AUTOSAR XML
package /Cluster
  can cluster CAN: speed=50000
    physical channels CAN
      physical-channel:
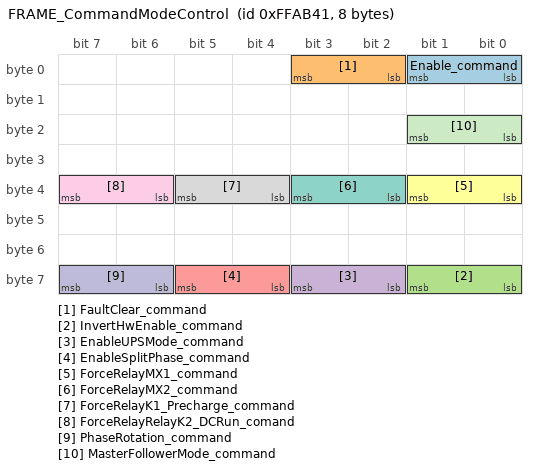
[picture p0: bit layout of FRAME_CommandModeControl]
        frame FRAME_CommandModeControl: id 0xFFAB41, frame-length=8, can-addressing-mode=EXTENDED
          pdu PDU_CommandModeControl: length=64
            signal Enable_command: start 1, 2 bit, big-endian, data-type=DataType/Enable_command
            signal FaultClear_command: start 3, 2 bit, big-endian, data-type=DataType/FaultClear_command
            signal InvertHwEnable_command: start 57, 2 bit, big-endian, data-type=DataType/InvertHwEnable_command
            signal EnableUPSMode_command: start 59, 2 bit, big-endian, data-type=DataType/EnableUPSMode_command
            signal EnableSplitPhase_command: start 61, 2 bit, big-endian, data-type=DataType/EnableSplitPhase_command
            signal ForceRelayMX1_command: start 33, 2 bit, big-endian, data-type=DataType/ForceRelayMX1_command
            signal ForceRelayMX2_command: start 35, 2 bit, big-endian, data-type=DataType/ForceRelayMX2_command
            signal ForceRelayK1_Precharge_command: start 37, 2 bit, big-endian, data-type=DataType/ForceRelayK1_Precharge_command
            signal ForceRelayRelayK2_DCRun_comand: start 39, 2 bit, big-endian, data-type=DataType/ForceRelayRelayK2_DCRun_comand
            signal PhaseRotation_command: start 63, 2 bit, big-endian, data-type=DataType/PhaseRotation_command
            signal MasterFollowerMode_command: start 17, 2 bit, big-endian, data-type=DataType/MasterFollowerMode_command
        frame FRAME_CommandPower: id 0xCFFAC41, frame-length=8, can-addressing-mode=EXTENDED
          pdu PDU_CommandPower: length=64
            signal RealPower command: start 7, 32 bit, big-endian, data-type=RealPower command
            signal ReactivePower_command: start 39, 32 bit, big-endian, data-type=DataType/ReactivePower_command
        frame FRAME_CommandVF: id 0xCFFAE41, frame-length=8, can-addressing-mode=EXTENDED
          pdu PDU_CommandVF: length=64
            signal Voltage_command: start 7, 16 bit, big-endian, data-type=DataType/Voltage_command
            signal Frequency_command: start 23, 16 bit, big-endian, data-type=DataType/Frequency_command
        frame FRAME_MasterMeasuredPower: id 0xCFFCAF6, frame-length=8, can-addressing-mode=EXTENDED
          pdu PDU_MasterMeasuredPower: length=64
            signal RealPower_measured: start 7, 32 bit, big-endian, data-type=DataType/RealPower_measured
            signal ReactivePower_measured: start 39, 32 bit, big-endian, data-type=DataType/ReactivePower_measured
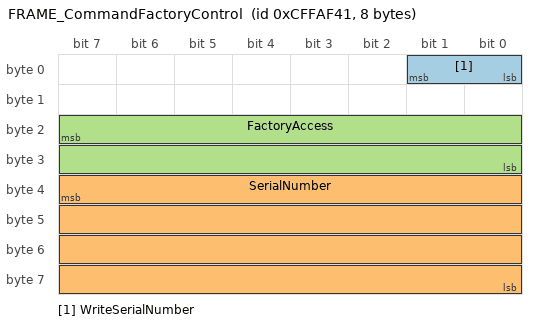
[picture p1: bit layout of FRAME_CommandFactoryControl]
        frame FRAME_CommandFactoryControl: id 0xCFFAF41, frame-length=8, can-addressing-mode=EXTENDED
          pdu PDU_CommandFactoryControl: length=64
            signal WriteSerialNumber: start 1, 2 bit, big-endian, data-type=WriteSerialNumber
            signal SerialNumber: start 39, 32 bit, big-endian, data-type=DataType/SerialNumber
            signal FactoryAccess: start 23, 16 bit, big-endian, data-type=FactoryAccess
        frame FRAME_CommandSetNVParam: id 0xCFFAA41, frame-length=8, can-addressing-mode=EXTENDED
          pdu PDU_CommandSetNVParam: length=64
            signal CommandSetNVParam_MUX: start 7, 16 bit, big-endian, data-type=CommandSetNVParam_MUX
            signal Dummy: start 23, 16 bit, big-endian, data-type=DataType/Dummy
            signal VUnder50pct: start 23, 16 bit, big-endian, data-type=DataType/VUnder50pct
            signal V50to88pct: start 39, 16 bit, big-endian, data-type=DataType/V50to88pct
            signal V110to120pct: start 55, 16 bit, big-endian, data-type=DataType/V110to120pct
            signal VOver120: start 23, 16 bit, big-endian, data-type=DataType/VOver120
            signal FreqHi: start 23, 16 bit, big-endian, data-type=DataType/FreqHi
            signal FreqLo: start 39, 16 bit, big-endian, data-type=DataType/FreqLo
            signal FreqVeryLo: start 55, 16 bit, big-endian, data-type=DataType/FreqVeryLo
            signal FreqVeryLo: start 23, 16 bit, big-endian, data-type=DataType/FreqVeryLo
            signal FreqLo: start 39, 16 bit, big-endian, data-type=DataType/FreqLo
            signal FreqHi: start 55, 16 bit, big-endian, data-type=DataType/FreqHi
            signal NodeID: start 23, 8 bit, big-endian, data-type=NodeID
            signal SA_Mask: start 31, 8 bit, big-endian, data-type=SA_Mask
            signal Baudrate: start 39, 4 bit, big-endian, data-type=Baudrate
            signal ThermalOverload: start 17, 2 bit, big-endian, data-type=DataType/ThermalOverload
            signal MX1Open: start 23, 16 bit, big-endian, data-type=MX1Open
            signal MX1Close: start 39, 16 bit, big-endian, data-type=MX1Close
            signal MX2Open: start 55, 16 bit, big-endian, data-type=MX2Open
            signal MX2Close: start 23, 16 bit, big-endian, data-type=MX2Close
            signal K1Open: start 39, 16 bit, big-endian, data-type=K1Open
            signal K1Close: start 55, 16 bit, big-endian, data-type=K1Close
            signal K2Open: start 23, 16 bit, big-endian, data-type=K2Open
            signal K2Close: start 39, 16 bit, big-endian, data-type=K2Close
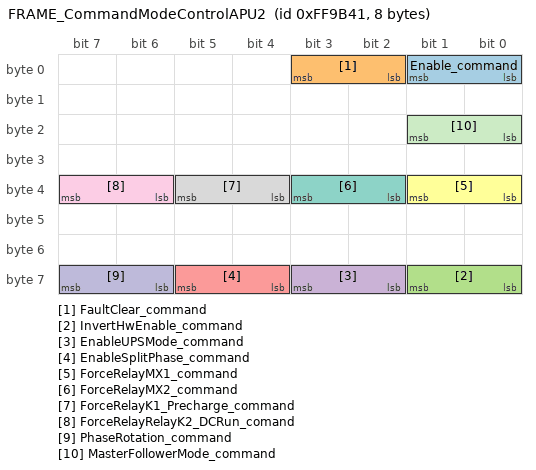
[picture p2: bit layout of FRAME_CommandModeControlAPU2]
        frame FRAME_CommandModeControlAPU2: id 0xFF9B41, frame-length=8, can-addressing-mode=EXTENDED
          pdu PDU_CommandModeControlAPU2: length=64
            signal Enable_command: start 1, 2 bit, big-endian, data-type=DataType/Enable_command
            signal FaultClear_command: start 3, 2 bit, big-endian, data-type=DataType/FaultClear_command
            signal InvertHwEnable_command: start 57, 2 bit, big-endian, data-type=DataType/InvertHwEnable_command
            signal EnableUPSMode_command: start 59, 2 bit, big-endian, data-type=DataType/EnableUPSMode_command
            signal EnableSplitPhase_command: start 61, 2 bit, big-endian, data-type=DataType/EnableSplitPhase_command
            signal ForceRelayMX1_command: start 33, 2 bit, big-endian, data-type=DataType/ForceRelayMX1_command
            signal ForceRelayMX2_command: start 35, 2 bit, big-endian, data-type=DataType/ForceRelayMX2_command
            signal ForceRelayK1_Precharge_command: start 37, 2 bit, big-endian, data-type=DataType/ForceRelayK1_Precharge_command
            signal ForceRelayRelayK2_DCRun_comand: start 39, 2 bit, big-endian, data-type=DataType/ForceRelayRelayK2_DCRun_comand
            signal PhaseRotation_command: start 63, 2 bit, big-endian, data-type=DataType/PhaseRotation_command
            signal MasterFollowerMode_command: start 17, 2 bit, big-endian, data-type=DataType/MasterFollowerMode_command
        frame FRAME_CommandPowerAPU2: id 0xCFF9C41, frame-length=8, can-addressing-mode=EXTENDED
          pdu PDU_CommandPowerAPU2: length=64
            signal RealPower_command: start 7, 32 bit, big-endian, data-type=RealPower_command
            signal ReactivePower_command: start 39, 32 bit, big-endian, data-type=DataType/ReactivePower_command
        frame FRAME_CommandVFAPU2: id 0xCFF9E41, frame-length=8, can-addressing-mode=EXTENDED
          pdu PDU_CommandVFAPU2: length=64
            signal Voltage_command: start 7, 16 bit, big-endian, data-type=DataType/Voltage_command
            signal Frequency_command: start 23, 16 bit, big-endian, data-type=DataType/Frequency_command
        frame FRAME_MasterMeasuredPowerAPU2: id 0xCFFCAF7, frame-length=8, can-addressing-mode=EXTENDED
          pdu PDU_MasterMeasuredPowerAPU2: length=64
            signal RealPower_measured: start 7, 32 bit, big-endian, data-type=DataType/RealPower_measured
            signal ReactivePower_measured: start 39, 32 bit, big-endian, data-type=DataType/ReactivePower_measured
        frame FRAME_justString: id 0x1CFFACC0, frame-length=8, can-addressing-mode=EXTENDED
          pdu PDU_justString: length=64
        frame FRAME_stringAndOther: id 0x1CFFABC0, frame-length=8, can-addressing-mode=EXTENDED
          pdu PDU_stringAndOther: length=64
            signal RealPower_measured: start 7, 32 bit, big-endian, data-type=DataType/RealPower_measured
        frame FRAME_StatusMeasuredPower: id 0xCFFCAF7, frame-length=8, can-addressing-mode=EXTENDED
          pdu PDU_StatusMeasuredPower: length=64
            signal RealPower_measured: start 7, 32 bit, big-endian, data-type=DataType/RealPower_measured
            signal ReactivePower_measured: start 39, 32 bit, big-endian, data-type=DataType/ReactivePower_measured
        frame FRAME_StatusCommandedPower: id 0x18FFC4F7, frame-length=8, can-addressing-mode=EXTENDED
          pdu PDU_StatusCommandedPower: length=64
            signal RealPower_echo: start 7, 32 bit, big-endian, data-type=RealPower_echo
            signal ReactivePower_echo: start 39, 32 bit, big-endian, data-type=ReactivePower_echo
        frame FRAME_StatusBits: id 0xCFFC3F7, frame-length=8, can-addressing-mode=EXTENDED
          pdu PDU_StatusBits: length=64
            signal State_status: start 3, 4 bit, big-endian, data-type=State_status
            signal MX2Permissive_status: start 19, 2 bit, big-endian, data-type=MX2Permissive_status
            signal PowerAvailAC_status: start 11, 2 bit, big-endian, data-type=PowerAvailAC_status
            signal PowerAvailDC_status: start 13, 2 bit, big-endian, data-type=PowerAvailDC_status
            signal PowerCircuitEnabled_status: start 15, 2 bit, big-endian, data-type=PowerCircuitEnabled_status
            signal HardwareEnable_status: start 9, 2 bit, big-endian, data-type=HardwareEnable_status
            signal Enable_echo: start 5, 2 bit, big-endian, data-type=Enable_echo
            signal FaultClr_echo: start 7, 2 bit, big-endian, data-type=FaultClr_echo
            signal MessageValidModeControl_status: start 25, 2 bit, big-endian, data-type=MessageValidModeControl_status
            signal MX1Permissive_status: start 17, 2 bit, big-endian, data-type=MX1Permissive_status
            signal K2DCRunPermissive_status: start 23, 2 bit, big-endian, data-type=K2DCRunPermissive_status
            signal K1PrechargePermissive_status: start 21, 2 bit, big-endian, data-type=K1PrechargePermissive_status
            signal MessageValidPowerCMD_status: start 27, 2 bit, big-endian, data-type=MessageValidPowerCMD_status
            signal MessageValidVF_status: start 29, 2 bit, big-endian, data-type=MessageValidVF_status
            signal CANbus_status: start 31, 2 bit, big-endian, data-type=CANbus_status
            signal EnableUPSMode_echo: start 33, 2 bit, big-endian, data-type=EnableUPSMode_echo
            signal EnableSplitPhase_echo: start 35, 2 bit, big-endian, data-type=EnableSplitPhase_echo
            signal PhaseRotation_status: start 37, 2 bit, big-endian, data-type=PhaseRotation_status
            signal LineVoltageDetected_status: start 39, 2 bit, big-endian, data-type=LineVoltageDetected_status
            signal PhaseRotation_echo: start 41, 2 bit, big-endian, data-type=PhaseRotation_echo
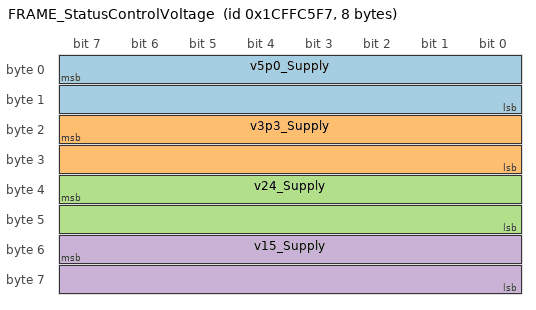
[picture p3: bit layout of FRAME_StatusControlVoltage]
        frame FRAME_StatusControlVoltage: id 0x1CFFC5F7, frame-length=8, can-addressing-mode=EXTENDED
          pdu PDU_StatusControlVoltage: length=64
            signal v5p0_Supply: start 7, 16 bit, big-endian, data-type=v5p0_Supply
            signal v3p3_Supply: start 23, 16 bit, big-endian, data-type=v3p3_Supply
            signal v24_Supply: start 39, 16 bit, big-endian, data-type=v24_Supply
            signal v15_Supply: start 55, 16 bit, big-endian, data-type=v15_Supply
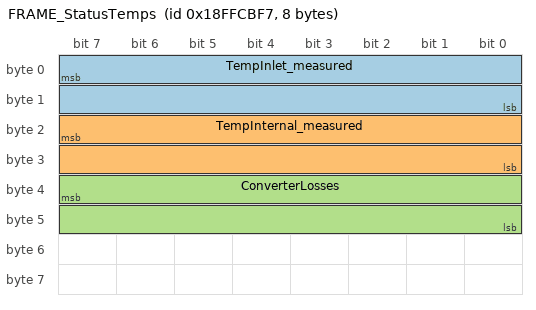
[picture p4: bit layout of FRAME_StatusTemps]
        frame FRAME_StatusTemps: id 0x18FFCBF7, frame-length=8, can-addressing-mode=EXTENDED
          pdu PDU_StatusTemps: length=64
            signal TempInlet_measured: start 7, 16 bit, big-endian, data-type=TempInlet_measured
            signal TempInternal_measured: start 23, 16 bit, big-endian, data-type=TempInternal_measured
            signal ConverterLosses: start 39, 16 bit, big-endian, data-type=ConverterLosses
        frame FRAME_StatusFaults: id 0xCFFC8F7, frame-length=8, can-addressing-mode=EXTENDED
          pdu PDU_StatusFaults: length=64
            signal BridgeAVoltageOk_status: start 59, 1 bit, big-endian, data-type=BridgeAVoltageOk_status
            signal OvercurrentAC_status: start 3, 2 bit, big-endian, data-type=OvercurrentAC_status
            signal BridgeBVoltageOk_status: start 43, 1 bit, big-endian, data-type=BridgeBVoltageOk_status
            signal OvervoltageDC_status: start 9, 2 bit, big-endian, data-type=OvervoltageDC_status
            signal OvertempPowerDevice_status: start 15, 2 bit, big-endian, data-type=OvertempPowerDevice_status
            signal OvertempInternal_status: start 13, 2 bit, big-endian, data-type=OvertempInternal_status
            signal LossValidControlMessage_status: start 23, 4 bit, big-endian, data-type=LossValidControlMessage_status
            signal UndervoltageDC_status: start 11, 2 bit, big-endian, data-type=UndervoltageDC_status
            signal ControlHardwareFail_status: start 19, 4 bit, big-endian, data-type=ControlHardwareFail_status
            signal OvercurrentDC_status: start 7, 2 bit, big-endian, data-type=OvercurrentDC_status
            signal GeneralFault_status: start 1, 2 bit, big-endian, data-type=GeneralFault_status
            signal LossOfAC_status: start 5, 2 bit, big-endian, data-type=LossOfAC_status
            signal EStopShutdown_status: start 25, 2 bit, big-endian, data-type=EStopShutdown_status
            signal BridgeAFault_status: start 58, 3 bit, big-endian, data-type=BridgeAFault_status
            signal BridgeBFault_status: start 42, 3 bit, big-endian, data-type=BridgeBFault_status
            signal IllegalTransition_status: start 27, 2 bit, big-endian, data-type=IllegalTransition_status
            signal InvalidEEHeader_status: start 29, 2 bit, big-endian, data-type=InvalidEEHeader_status
            signal InvalidEESection_status: start 31, 2 bit, big-endian, data-type=InvalidEESection_status
            signal ThermalOverload: start 33, 2 bit, big-endian, data-type=DataType/ThermalOverload
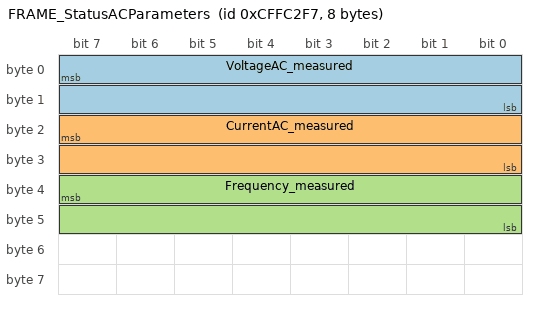
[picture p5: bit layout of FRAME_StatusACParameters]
        frame FRAME_StatusACParameters: id 0xCFFC2F7, frame-length=8, can-addressing-mode=EXTENDED
          pdu PDU_StatusACParameters: length=64
            signal VoltageAC_measured: start 7, 16 bit, big-endian, data-type=VoltageAC_measured
            signal CurrentAC_measured: start 23, 16 bit, big-endian, data-type=CurrentAC_measured
            signal Frequency_measured: start 39, 16 bit, big-endian, data-type=Frequency_measured
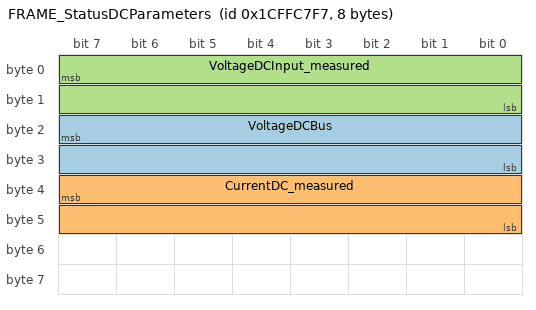
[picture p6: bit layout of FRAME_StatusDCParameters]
        frame FRAME_StatusDCParameters: id 0x1CFFC7F7, frame-length=8, can-addressing-mode=EXTENDED
          pdu PDU_StatusDCParameters: length=64
            signal VoltageDCBus: start 23, 16 bit, big-endian, data-type=VoltageDCBus
            signal CurrentDC_measured: start 39, 16 bit, big-endian, data-type=CurrentDC_measured
            signal VoltageDCInput_measured: start 7, 16 bit, big-endian, data-type=VoltageDCInput_measured
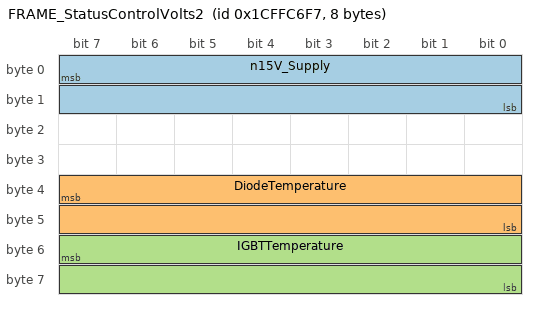
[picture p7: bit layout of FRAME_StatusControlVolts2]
        frame FRAME_StatusControlVolts2: id 0x1CFFC6F7, frame-length=8, can-addressing-mode=EXTENDED
          pdu PDU_StatusControlVolts2: length=64
            signal n15V_Supply: start 7, 16 bit, big-endian, data-type=n15V_Supply
            signal DiodeTemperature: start 39, 16 bit, big-endian, data-type=DiodeTemperature
            signal IGBTTemperature: start 55, 16 bit, big-endian, data-type=IGBTTemperature
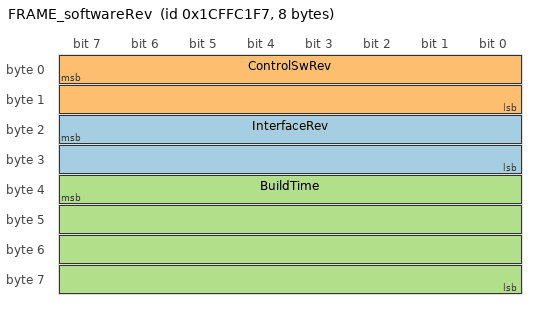
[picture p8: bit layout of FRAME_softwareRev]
        frame FRAME_softwareRev: id 0x1CFFC1F7, frame-length=8, can-addressing-mode=EXTENDED
          pdu PDU_softwareRev: length=64
            signal InterfaceRev: start 23, 16 bit, big-endian, data-type=InterfaceRev
            signal ControlSwRev: start 7, 16 bit, big-endian, data-type=ControlSwRev
            signal BuildTime: start 39, 32 bit, big-endian, data-type=BuildTime
        frame FRAME_StatusCommandVF: id 0x18FFC9F7, frame-length=8, can-addressing-mode=EXTENDED
          pdu PDU_StatusCommandVF: length=64
            signal Voltage_echo: start 7, 16 bit, big-endian, data-type=Voltage_echo
            signal Frequency_echo: start 23, 16 bit, big-endian, data-type=Frequency_echo
        frame FRAME_serialNumber: id 0x1CFFCCF7, frame-length=8, can-addressing-mode=EXTENDED
          pdu PDU_serialNumber: length=64
            signal SerialNumber: start 7, 32 bit, big-endian, data-type=DataType/SerialNumber
        frame FRAME_softwareRevHash: id 0x1CFFCDF7, frame-length=8, can-addressing-mode=EXTENDED
          pdu PDU_softwareRevHash: length=64
            signal Hash: start 7, 28 bit, big-endian, data-type=Hash
        frame FRAME_StatusNVParam: id 0x1CFFA9F7, frame-length=8, can-addressing-mode=EXTENDED
          pdu PDU_StatusNVParam: length=64
            signal StatusNVParam_MUX: start 7, 16 bit, big-endian, data-type=StatusNVParam_MUX
            signal Dummy: start 23, 16 bit, big-endian, data-type=DataType/Dummy
            signal VUnder50pct: start 23, 16 bit, big-endian, data-type=DataType/VUnder50pct
            signal V50to88pct: start 39, 16 bit, big-endian, data-type=DataType/V50to88pct
            signal V110to120pct: start 55, 16 bit, big-endian, data-type=DataType/V110to120pct
            signal VOver120: start 23, 16 bit, big-endian, data-type=DataType/VOver120
            signal FreqHi: start 23, 16 bit, big-endian, data-type=DataType/FreqHi
            signal FreqLo: start 39, 16 bit, big-endian, data-type=DataType/FreqLo
            signal FreqVeryLo: start 55, 16 bit, big-endian, data-type=DataType/FreqVeryLo
            signal FreqVeryLo: start 23, 16 bit, big-endian, data-type=DataType/FreqVeryLo
            signal FreqLo: start 39, 16 bit, big-endian, data-type=DataType/FreqLo
            signal FreqHi: start 55, 16 bit, big-endian, data-type=DataType/FreqHi
            signal StatusNodeID: start 23, 8 bit, big-endian, data-type=StatusNodeID
            signal StatusSA_Mask: start 31, 8 bit, big-endian, data-type=StatusSA_Mask
            signal StatusBaudrate: start 39, 4 bit, big-endian, data-type=StatusBaudrate
            signal StatusThermalOverload: start 17, 2 bit, big-endian, data-type=StatusThermalOverload
            signal StatusMX1Open: start 23, 16 bit, big-endian, data-type=StatusMX1Open
            signal StatusMX1Close: start 39, 16 bit, big-endian, data-type=StatusMX1Close
            signal StatusMX2Open: start 55, 16 bit, big-endian, data-type=StatusMX2Open
            signal StatusMX2Close: start 23, 16 bit, big-endian, data-type=StatusMX2Close
            signal StatusK1Open: start 39, 16 bit, big-endian, data-type=StatusK1Open
            signal StatusK1Close: start 55, 16 bit, big-endian, data-type=StatusK1Close
            signal StatusK2Open: start 23, 16 bit, big-endian, data-type=StatusK2Open
            signal StatusK2Close: start 39, 16 bit, big-endian, data-type=StatusK2Close
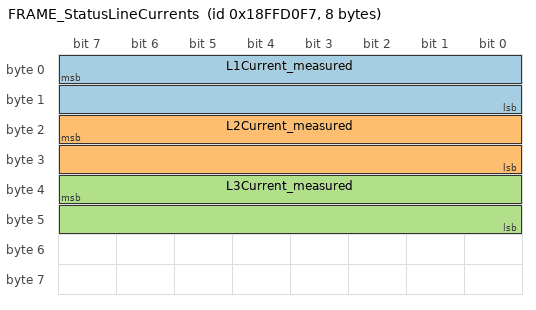
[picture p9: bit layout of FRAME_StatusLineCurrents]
        frame FRAME_StatusLineCurrents: id 0x18FFD0F7, frame-length=8, can-addressing-mode=EXTENDED
          pdu PDU_StatusLineCurrents: length=64
            signal L1Current_measured: start 7, 16 bit, big-endian, data-type=L1Current_measured
            signal L2Current_measured: start 23, 16 bit, big-endian, data-type=L2Current_measured
            signal L3Current_measured: start 39, 16 bit, big-endian, data-type=L3Current_measured
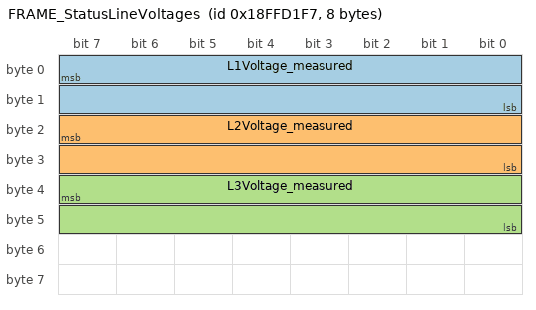
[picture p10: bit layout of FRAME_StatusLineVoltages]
        frame FRAME_StatusLineVoltages: id 0x18FFD1F7, frame-length=8, can-addressing-mode=EXTENDED
          pdu PDU_StatusLineVoltages: length=64
            signal L1Voltage_measured: start 7, 16 bit, big-endian, data-type=L1Voltage_measured
            signal L2Voltage_measured: start 23, 16 bit, big-endian, data-type=L2Voltage_measured
            signal L3Voltage_measured: start 39, 16 bit, big-endian, data-type=L3Voltage_measured
package /ISignal
  35 x i signal:
    Enable_command: system-signal=Signal/Enable_command
    FaultClear_command: system-signal=Signal/FaultClear_command
    InvertHwEnable_command: system-signal=Signal/InvertHwEnable_command
    EnableUPSMode_command: system-signal=Signal/EnableUPSMode_command
    EnableSplitPhase_command: system-signal=Signal/EnableSplitPhase_command
    ForceRelayMX1_command: system-signal=Signal/ForceRelayMX1_command
    ForceRelayMX2_command: system-signal=Signal/ForceRelayMX2_command
    ForceRelayK1_Precharge_command: system-signal=Signal/ForceRelayK1_Precharge_command
    ForceRelayRelayK2_DCRun_comand: system-signal=Signal/ForceRelayRelayK2_DCRun_comand
    PhaseRotation_command: system-signal=Signal/PhaseRotation_command
    MasterFollowerMode_command: system-signal=Signal/MasterFollowerMode_command
    ReactivePower_command: system-signal=Signal/ReactivePower_command
    Voltage_command: system-signal=Signal/Voltage_command
    Frequency_command: system-signal=Signal/Frequency_command
    RealPower_measured: system-signal=Signal/RealPower_measured
    ReactivePower_measured: system-signal=Signal/ReactivePower_measured
    SerialNumber: system-signal=Signal/SerialNumber
    Dummy: system-signal=Signal/Dummy
    VUnder50pct: system-signal=Signal/VUnder50pct
    V50to88pct: system-signal=Signal/V50to88pct
    V110to120pct: system-signal=Signal/V110to120pct
    VOver120: system-signal=Signal/VOver120
    FreqHi: system-signal=Signal/FreqHi
    FreqLo: system-signal=Signal/FreqLo
    FreqVeryLo: system-signal=Signal/FreqVeryLo
    FreqVeryLo: system-signal=Signal/FreqVeryLo
    FreqLo: system-signal=Signal/FreqLo
    FreqHi: system-signal=Signal/FreqHi
    ThermalOverload: system-signal=Signal/ThermalOverload
    RealPower_measured: system-signal=Signal/RealPower_measured
    ReactivePower_measured: system-signal=Signal/ReactivePower_measured
    RealPower_measured: system-signal=Signal/RealPower_measured
    FreqHi: system-signal=Signal/FreqHi
    FreqLo: system-signal=Signal/FreqLo
    FreqVeryLo: system-signal=Signal/FreqVeryLo
package /Signal
  35 x system signal:
    Enable_command: length=2, data-type=DataType/Enable_command
    FaultClear_command: length=2, data-type=DataType/FaultClear_command
    InvertHwEnable_command: length=2, data-type=DataType/InvertHwEnable_command
    EnableUPSMode_command: length=2, data-type=DataType/EnableUPSMode_command
    EnableSplitPhase_command: length=2, data-type=DataType/EnableSplitPhase_command
    ForceRelayMX1_command: length=2, data-type=DataType/ForceRelayMX1_command
    ForceRelayMX2_command: length=2, data-type=DataType/ForceRelayMX2_command
    ForceRelayK1_Precharge_command: length=2, data-type=DataType/ForceRelayK1_Precharge_command
    ForceRelayRelayK2_DCRun_comand: length=2, data-type=DataType/ForceRelayRelayK2_DCRun_comand
    PhaseRotation_command: length=2, data-type=DataType/PhaseRotation_command
    MasterFollowerMode_command: length=2, data-type=DataType/MasterFollowerMode_command
    ReactivePower_command: length=32, data-type=DataType/ReactivePower_command
    Voltage_command: length=16, data-type=DataType/Voltage_command
    Frequency_command: length=16, data-type=DataType/Frequency_command
    RealPower_measured: length=32, data-type=DataType/RealPower_measured
    ReactivePower_measured: length=32, data-type=DataType/ReactivePower_measured
    SerialNumber: length=32, data-type=DataType/SerialNumber
    Dummy: length=16, data-type=DataType/Dummy
    VUnder50pct: length=16, data-type=DataType/VUnder50pct
    V50to88pct: length=16, data-type=DataType/V50to88pct
    V110to120pct: length=16, data-type=DataType/V110to120pct
    VOver120: length=16, data-type=DataType/VOver120
    FreqHi: length=16, data-type=DataType/FreqHi
    FreqLo: length=16, data-type=DataType/FreqLo
    FreqVeryLo: length=16, data-type=DataType/FreqVeryLo
    FreqVeryLo: length=16, data-type=DataType/FreqVeryLo
    FreqLo: length=16, data-type=DataType/FreqLo
    FreqHi: length=16, data-type=DataType/FreqHi
    ThermalOverload: length=2, data-type=DataType/ThermalOverload
    RealPower_measured: length=32, data-type=DataType/RealPower_measured
    ReactivePower_measured: length=32, data-type=DataType/ReactivePower_measured
    RealPower_measured: length=32, data-type=DataType/RealPower_measured
    FreqHi: length=16, data-type=DataType/FreqHi
    FreqLo: length=16, data-type=DataType/FreqLo
    FreqVeryLo: length=16, data-type=DataType/FreqVeryLo
package /DataType
  158 x integer type:
    Enable_command: compu {0=Disable, 1=Enable, 2=Error, 3=N/A, phys=raw}
    FaultClear_command: compu {0=Normal, 1=Clear Faults, 2=Error, 3=N/A, phys=raw}
    InvertHwEnable_command: compu {0=No invert, 1=Invert, 2=Error, 3=N/A, phys=raw}
    EnableUPSMode_command: compu {0=Disable, 1=Enable, 2=Error, 3=N/A, phys=raw}
    EnableSplitPhase_command: compu-method=Semantics/EnableSplitPhase_command
    ForceRelayMX1_command: compu {0=Normal, 1=Force On, 2=Error, 3=N/A, phys=raw}
    ForceRelayMX2_command: compu {0=Normal, 1=Force On, 2=Error, 3=N/A, phys=raw}
    ForceRelayK1_Precharge_command: compu {0=Normal, 1=Force On, 2=Error, 3=N/A, phys=raw}
    ForceRelayRelayK2_DCRun_comand: compu {0=Normal, 1=Force On, 2=Error, 3=N/A, phys=raw}
    PhaseRotation_command: compu {0=Negative, 1=Positive, 2=Error, 3=N/A, phys=raw}
    MasterFollowerMode_command: compu {0=Master, 1=Follower, 2=Error, 3=N/A, phys=raw}
    RealPower command: compu {phys=raw}
    ReactivePower_command: compu {phys=raw}
    Voltage_command: compu {phys=raw*0.1}
    Frequency_command: compu {phys=raw*0.1}
    RealPower_measured: compu {phys=raw}
    ReactivePower_measured: compu {phys=raw}
    WriteSerialNumber: compu {0=Disable, 1=Enable, 2=Error, 3=N/A, phys=raw}
    SerialNumber: compu {phys=raw}
    FactoryAccess: compu {phys=raw}
    CommandSetNVParam_MUX: compu {0=Param0, 1=LVM_ClearingTimes1, 2=LVM_ClearingTimes2, 3=LFM_Limits, 4=LFM_ClearingTimes, 5=J1939_Interface, 6=Fault_Config, 7=ContactorDelays1, 8=ContactorDelays2, 10=ContactorDelays3, phys=raw}
    Dummy: compu {phys=raw}
    VUnder50pct: compu {phys=raw}
    V50to88pct: compu {phys=raw}
    V110to120pct: compu {phys=raw}
    VOver120: compu {phys=raw}
    FreqHi: compu {phys=raw}
    FreqLo: compu {phys=raw}
    FreqVeryLo: compu {phys=raw}
    FreqVeryLo: compu {phys=raw}
    FreqLo: compu {phys=raw}
    FreqHi: compu {phys=raw}
    NodeID: compu {phys=raw}
    SA_Mask: compu {phys=raw}
    Baudrate: compu {0=125K, 1=250K, 2=500K, 3=1M, phys=raw}
    ThermalOverload: compu {0=Normal, 1=Fault Active, 2=Error, 3=N/A, phys=raw}
    MX1Open: compu {phys=raw}
    MX1Close: compu {phys=raw}
    MX2Open: compu {phys=raw}
    MX2Close: compu {phys=raw}
    K1Open: compu {phys=raw}
    K1Close: compu {phys=raw}
    K2Open: compu {phys=raw}
    K2Close: compu {phys=raw}
    Enable_command: compu {0=Disable, 1=Enable, 2=Error, 3=N/A, phys=raw}
    FaultClear_command: compu {0=Normal, 1=Clear Faults, 2=Error, 3=N/A, phys=raw}
    InvertHwEnable_command: compu {0=No invert, 1=Invert, 2=Error, 3=N/A, phys=raw}
    EnableUPSMode_command: compu {0=Disable, 1=Enable, 2=Error, 3=N/A, phys=raw}
    EnableSplitPhase_command: compu-method=Semantics/EnableSplitPhase_command
    ForceRelayMX1_command: compu {0=Normal, 1=Force On, 2=Error, 3=N/A, phys=raw}
    ForceRelayMX2_command: compu {0=Normal, 1=Force On, 2=Error, 3=N/A, phys=raw}
    ForceRelayK1_Precharge_command: compu {0=Normal, 1=Force On, 2=Error, 3=N/A, phys=raw}
    ForceRelayRelayK2_DCRun_comand: compu {0=Normal, 1=Force On, 2=Error, 3=N/A, phys=raw}
    PhaseRotation_command: compu {0=Negative, 1=Positive, 2=Error, 3=N/A, phys=raw}
    MasterFollowerMode_command: compu {0=Master, 1=Follower, 2=Error, 3=N/A, phys=raw}
    RealPower_command: compu {phys=raw}
    ReactivePower_command: compu {phys=raw}
    Voltage_command: compu {phys=raw*0.1}
    Frequency_command: compu {phys=raw*0.1}
    RealPower_measured: compu {phys=raw}
    ReactivePower_measured: compu {phys=raw}
    RealPower_measured: compu {phys=raw}
    RealPower_measured: compu {phys=raw}
    ReactivePower_measured: compu {phys=raw}
    RealPower_echo: compu {phys=raw}
    ReactivePower_echo: compu {phys=raw}
    State_status: compu {0=Power On Reset, and a quoted comma, 1=Ready, 2=Following, 3=Fault, 4=Forming, 5..15=N/A, phys=raw}
    MX2Permissive_status: compu {0=Open, 1=Closed, 2=Error, 3=N/A, phys=raw}
    PowerAvailAC_status: compu {0=None, 1=Available, 2=Error, 3=N/A, phys=raw}
    PowerAvailDC_status: compu {0=None, 1=Available, 2=Error, 3=N/A, phys=raw}
    PowerCircuitEnabled_status: compu {0=Disabled, 1=Enabled, 2=Error, 3=N/A, phys=raw}
    HardwareEnable_status: compu {0=Not Active, 1=Active, 2=Error, 3=N/A, phys=raw}
    Enable_echo: compu {0=Disable, 1=Enable, 2=Error, 3=N/A, phys=raw}
    FaultClr_echo: compu {0=Normal, 1=Clear Faults, 2=Error, 3=N/A, phys=raw}
    MessageValidModeControl_status: compu {0=Invalid, 1=Valid, 2=Error, 3=N/A, phys=raw}
    MX1Permissive_status: compu {0=Open, 1=Closed, 2=Error, 3=N/A, phys=raw}
    K2DCRunPermissive_status: compu {0=Open, 1=Closed, 2=Error, 3=N/A, phys=raw}
    K1PrechargePermissive_status: compu {0=Open, 1=Closed, 2=Error, 3=N/A, phys=raw}
    MessageValidPowerCMD_status: compu {0=Invalid, 1=Valid, 2=Error, 3=N/A, phys=raw}
    MessageValidVF_status: compu {0=Invalid, 1=Valid, 2=Error, 3=N/A, phys=raw}
    CANbus_status: compu {0=Normal, 1=Warning, 3=ErrorPassive, 4=N/A, phys=raw}
    EnableUPSMode_echo: compu {0=Disable, 1=Enable, 2=Error, 3=N/A, phys=raw}
    EnableSplitPhase_echo: compu {0=Normal - Three Phase Mode, 1=Enable Split Phase Mode, 2=Error, 3=N/A, phys=raw}
    PhaseRotation_status: compu {0=Negative, 1=Positive, 2=Error, 3=N/A, phys=raw}
    LineVoltageDetected_status: compu {0=No_Voltage, 1=Voltage_Detected, 2=Error, 3=N/A, phys=raw}
    PhaseRotation_echo: compu {0=Negative, 1=Positive, 2=Error, 3=N/A, phys=raw}
    v5p0_Supply: compu {phys=raw*0.01}
    v3p3_Supply: compu {phys=raw*0.01}
    v24_Supply: compu {phys=raw*0.01}
    v15_Supply: compu {phys=raw*0.01}
    TempInlet_measured: compu {phys=raw*0.1}
    TempInternal_measured: compu {phys=raw*0.1}
    ConverterLosses: compu {phys=raw}
    BridgeAVoltageOk_status: compu {0=Normal, 1=Fault Active, 2=Error, 3=N/A, phys=raw}
    OvercurrentAC_status: compu {0=Normal, 1=Fault Active, 2=Error, 3=N/A, phys=raw}
    BridgeBVoltageOk_status: compu {0=Normal, 1=Fault Active, 2=Error, 3=N/A, phys=raw}
    OvervoltageDC_status: compu {0=Normal, 1=Fault Active, 2=Error, 3=N/A, phys=raw}
    OvertempPowerDevice_status: compu {0=Normal, 1=Fault Active, 2=Error, 3=N/A, phys=raw}
    OvertempInternal_status: compu {0=Normal, 1=Fault Active, 2=Error, 3=N/A, phys=raw}
    LossValidControlMessage_status: compu {0=Normal, 1=Fault Active, 2=Error, 3=N/A, phys=raw}
    UndervoltageDC_status: compu {0=Normal, 1=Fault Active, 2=Error, 3=N/A, phys=raw}
    ControlHardwareFail_status: compu {0=Normal, 1=Fault Active, 2=Error, 3=N/A, phys=raw}
    OvercurrentDC_status: compu {0=Normal, 1=Fault Active, 2=Error, 3=N/A, phys=raw}
    GeneralFault_status: compu {0=Normal, 1=Fault Active, 2=Error, 3=N/A, phys=raw}
    LossOfAC_status: compu {0=Normal, 1=Fault Active, 2=Error, 3=N/A, phys=raw}
    EStopShutdown_status: compu {0=Normal, 1=Fault Active, 2=Error, 3=N/A, phys=raw}
    BridgeAFault_status: compu {0=Normal, 1=FLT_A, 2=N/A, 3=FLT_C, 4=OverVoltage, 5=FLT_B, 6=Overcurrent, 7=5V, phys=raw}
    BridgeBFault_status: compu {0=Normal, 1=FLT_A, 2=N/A, 3=FLT_C, 4=OverVoltage, 5=FLT_B, 6=Overcurrent, 7=5V, phys=raw}
    IllegalTransition_status: compu {0=Normal, 1=Fault Active, 2=Error, 3=N/A, phys=raw}
    InvalidEEHeader_status: compu {0=Normal, 1=Fault Active, 2=Error, 3=N/A, phys=raw}
    InvalidEESection_status: compu {0=Normal, 1=Fault Active, 2=Error, 3=N/A, phys=raw}
    ThermalOverload: compu {0=Normal, 1=Fault Active, 2=Error, 3=N/A, phys=raw}
    VoltageAC_measured: compu {phys=raw*0.1}
    CurrentAC_measured: compu {phys=raw}
    Frequency_measured: compu {phys=raw*0.1}
    VoltageDCBus: compu {phys=raw}
    CurrentDC_measured: compu {phys=raw}
    VoltageDCInput_measured: compu {phys=raw}
    n15V_Supply: compu {phys=raw*0.01}
    DiodeTemperature: compu {phys=raw}
    IGBTTemperature: compu {phys=raw}
    InterfaceRev: compu {phys=raw*0.01}
    ControlSwRev: compu {phys=raw*0.01}
    BuildTime: compu {phys=raw}
    Voltage_echo: compu {phys=raw*0.1}
    Frequency_echo: compu {phys=raw*0.1}
    SerialNumber: compu {phys=raw}
    Hash: compu {phys=raw}
    StatusNVParam_MUX: compu {0=ActParam0, 1=ActLVM_ClearingTimes1, 2=ActLVM_ClearingTimes2, 3=ActLFM_Limits, 4=ActLFM_ClearingTimes, 5=StatusJ1939_Interface, 6=StatusFault_Config, 7=StatusContactorDelays1, 8=StatusContactorDelays2, 9=StatusContactorDelays3, phys=raw}
    Dummy: compu {phys=raw}
    VUnder50pct: compu {phys=raw}
    V50to88pct: compu {phys=raw}
    V110to120pct: compu {phys=raw}
    VOver120: compu {phys=raw}
    FreqHi: compu {phys=raw}
    FreqLo: compu {phys=raw}
    FreqVeryLo: compu {phys=raw}
    FreqVeryLo: compu {phys=raw}
    FreqLo: compu {phys=raw}
    FreqHi: compu {phys=raw}
    StatusNodeID: compu {phys=raw}
    StatusSA_Mask: compu {phys=raw}
    StatusBaudrate: compu {0=125K, 1=250K, 2=500K, 3=1M, phys=raw}
    StatusThermalOverload: compu {0=Warning, 1=Fault, 2=Error, 3=N/A, phys=raw}
    StatusMX1Open: compu {phys=raw}
    StatusMX1Close: compu {phys=raw}
    StatusMX2Open: compu {phys=raw}
    StatusMX2Close: compu {phys=raw}
    StatusK1Open: compu {phys=raw}
    StatusK1Close: compu {phys=raw}
    StatusK2Open: compu {phys=raw}
    StatusK2Close: compu {phys=raw}
    L{1..3}Current_measured: compu {phys=raw}
    L{1..3}Voltage_measured: compu {phys=raw*0.1}
package /DataType/Semantics
  compu method Enable_command: 0=Disable, 1=Enable, 2=Error, 3=N/A, phys=raw
  compu method FaultClear_command: 0=Normal, 1=Clear Faults, 2=Error, 3=N/A, phys=raw
  compu method InvertHwEnable_command: 0=No invert, 1=Invert, 2=Error, 3=N/A, phys=raw
  compu method EnableUPSMode_command: 0=Disable, 1=Enable, 2=Error, 3=N/A, phys=raw
  compu method EnableSplitPhase_command: 0=Normal - Three Phase Mode, 1=Enable Split Phase Mode, 2=Error, 3=N/A, phys=raw
  compu method ForceRelayMX1_command: 0=Normal, 1=Force On, 2=Error, 3=N/A, phys=raw
  compu method ForceRelayMX2_command: 0=Normal, 1=Force On, 2=Error, 3=N/A, phys=raw
  compu method ForceRelayK1_Precharge_command: 0=Normal, 1=Force On, 2=Error, 3=N/A, phys=raw
  compu method ForceRelayRelayK2_DCRun_comand: 0=Normal, 1=Force On, 2=Error, 3=N/A, phys=raw
  compu method PhaseRotation_command: 0=Negative, 1=Positive, 2=Error, 3=N/A, phys=raw
  compu method MasterFollowerMode_command: 0=Master, 1=Follower, 2=Error, 3=N/A, phys=raw
  compu method ReactivePower_command: phys=raw
  compu method Voltage_command: phys=raw*0.1
  compu method Frequency_command: phys=raw*0.1
  compu method RealPower_measured: phys=raw
  compu method ReactivePower_measured: phys=raw
  compu method SerialNumber: phys=raw
  compu method Dummy: phys=raw
  compu method VUnder50pct: phys=raw
  compu method V50to88pct: phys=raw
  compu method V110to120pct: phys=raw
  compu method VOver120: phys=raw
  compu method FreqHi: phys=raw*0.1
  compu method FreqLo: phys=raw*0.1
  compu method FreqVeryLo: phys=raw*0.1
  compu method FreqVeryLo: phys=raw
  compu method FreqLo: phys=raw
  compu method FreqHi: phys=raw
  compu method ThermalOverload: 0=Warning, 1=Fault, 2=Error, 3=N/A, phys=raw
  compu method EnableSplitPhase_command: 0=Normal - Three Phase Mode, 1=Enable Split Phase Mode, 2=Error, 3=N/A, phys=raw
  compu method RealPower_measured: phys=raw
  compu method ReactivePower_measured: phys=raw
  compu method RealPower_measured: phys=raw
  compu method FreqHi: phys=raw*0.1
  compu method FreqLo: phys=raw*0.1
  compu method FreqVeryLo: phys=raw*0.1
